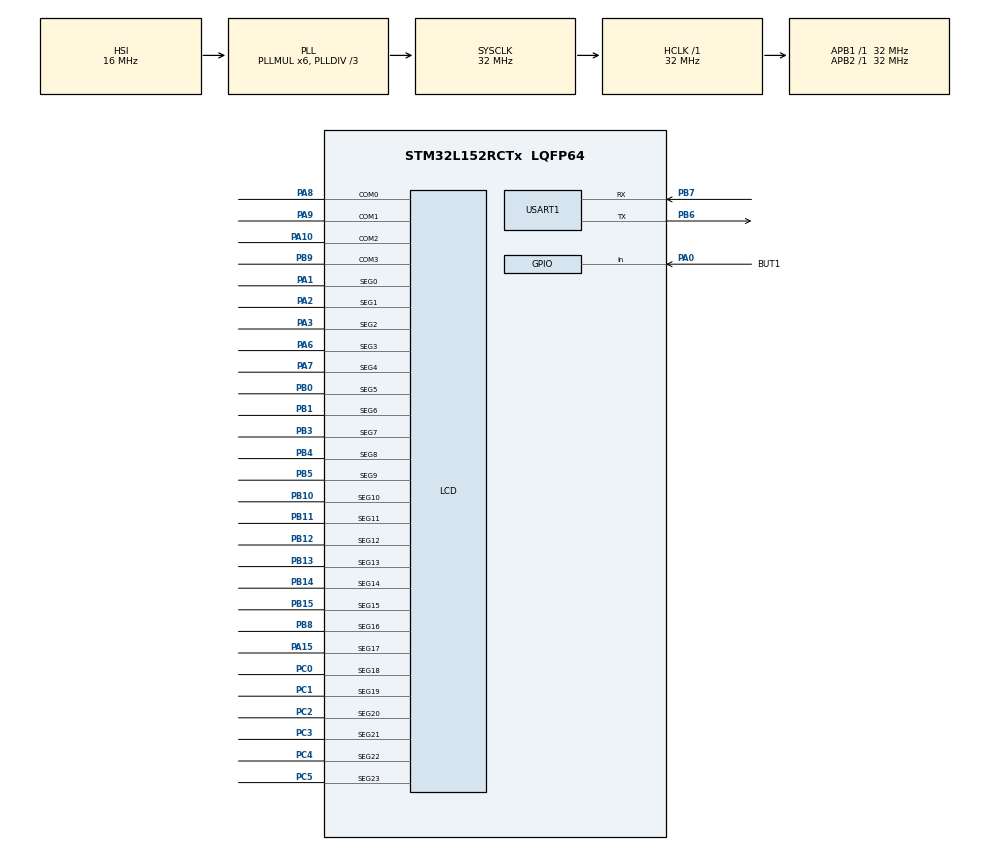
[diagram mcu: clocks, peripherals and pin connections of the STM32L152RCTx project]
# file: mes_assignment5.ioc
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LCD.Bias=LCD_BIAS_1_3
Mcu.Family=STM32L1
Mcu.Name=STM32L152RCTx
Mcu.Package=LQFP64
NVIC.PriorityGroup=NVIC_PRIORITYGROUP_0
NVIC.USART1_IRQn=true\:0\:0\:false\:false\:true\:true\:true\:true
PA0-WKUP1.GPIO_Label=BUT1
PA0-WKUP1.GPIO_PuPd=GPIO_PULLDOWN
PA0-WKUP1.Signal=GPIO_Input
PA1.Mode=SEG0
PA1.Signal=LCD_SEG0
PA10.Mode=1/4 Duty Cycle
PA10.Signal=LCD_COM2
PA15.Mode=SEG17
PA15.Signal=LCD_SEG17
PA2.Mode=SEG1
PA2.Signal=LCD_SEG1
PA3.Mode=SEG2
PA3.Signal=LCD_SEG2
PA6.Mode=SEG3
PA6.Signal=LCD_SEG3
PA7.Mode=SEG4
PA7.Signal=LCD_SEG4
PA8.Mode=1/4 Duty Cycle
PA8.Signal=LCD_COM0
PA9.Mode=1/4 Duty Cycle
PA9.Signal=LCD_COM1
PB0.Mode=SEG5
PB0.Signal=LCD_SEG5
PB1.Mode=SEG6
PB1.Signal=LCD_SEG6
PB10.Mode=SEG10
PB10.Signal=LCD_SEG10
PB11.Mode=SEG11
PB11.Signal=LCD_SEG11
PB12.Mode=SEG12
PB12.Signal=LCD_SEG12
PB13.Mode=SEG13
PB13.Signal=LCD_SEG13
PB14.Mode=SEG14
PB14.Signal=LCD_SEG14
PB15.Mode=SEG15
PB15.Signal=LCD_SEG15
PB3.Mode=SEG7
PB3.Signal=LCD_SEG7
PB4.Mode=SEG8
PB4.Signal=LCD_SEG8
PB5.Mode=SEG9
PB5.Signal=LCD_SEG9
PB6.Mode=Asynchronous
PB6.Signal=USART1_TX
PB7.Mode=Asynchronous
PB7.Signal=USART1_RX
PB8.Mode=SEG16
PB8.Signal=LCD_SEG16
PB9.Mode=1/4 Duty Cycle
PB9.Signal=LCD_COM3
PC0.Mode=SEG18
PC0.Signal=LCD_SEG18
PC1.Mode=SEG19
PC1.Signal=LCD_SEG19
PC2.Mode=SEG20
PC2.Signal=LCD_SEG20
PC3.Mode=SEG21
PC3.Signal=LCD_SEG21
PC4.Mode=SEG22
PC4.Signal=LCD_SEG22
PC5.Mode=SEG23
PC5.Signal=LCD_SEG23
ProjectManager.HeapSize=0x200
ProjectManager.StackSize=0x400
ProjectManager.TargetToolchain=STM32CubeIDE
RCC.48MHZClocksFreq_Value=48000000
RCC.AHBFreq_Value=32000000
RCC.APB1Freq_Value=32000000
RCC.APB1TimFreq_Value=32000000
RCC.APB2Freq_Value=32000000
RCC.APB2TimFreq_Value=32000000
RCC.HCLKFreq_Value=32000000
RCC.HSE_VALUE=8000000
RCC.HSI_VALUE=16000000
RCC.LSE_VALUE=32768
RCC.MSI_VALUE=2097000
RCC.PLLDIV=RCC_PLL_DIV3
RCC.PLLMUL=RCC_PLL_MUL6
RCC.RTCClockSelection=RCC_RTCCLKSOURCE_LSI
RCC.RTCClockSelectionVirtual=RCC_RTCCLKSOURCE_LSE
RCC.SYSCLKFreq_VALUE=32000000
RCC.SYSCLKSource=RCC_SYSCLKSOURCE_PLLCLK
RCC.USBOutput=48000000
RCC.VCOOutputFreq_Value=96000000
TIM5.Period=4294967295
TIM5.Prescaler=32000
USART1.VirtualMode=VM_ASYNC
VP_LCD_LCD_mux.Mode=Multiplex
VP_TIM5_VS_ClockSourceINT.Mode=Internal
board=STM32L152C-DISCO

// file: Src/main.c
/* USER CODE BEGIN Header */
/**
  ******************************************************************************
  * @file           : main.c
  * @brief          : Main program body
  ******************************************************************************
  * @attention
  *
  * Copyright (c) 2023 STMicroelectronics.
  * All rights reserved.
  *
  * This software is licensed under terms that can be found in the LICENSE file
  * in the root directory of this software component.
  * If no LICENSE file comes with this software, it is provided AS-IS.
  *
  ******************************************************************************
  */
/* USER CODE END Header */
#include "main.h"

/* USER CODE BEGIN Includes */
#include "stm32l152c_discovery_glass_lcd.h"
#include "console.h"
#include "applicationCommands.h"
/* USER CODE END Includes */

TIM_HandleTypeDef htim5;

UART_HandleTypeDef huart1;

void SystemClock_Config(void);
static void MX_GPIO_Init(void);
static void MX_USART1_UART_Init(void);
static void MX_TIM5_Init(void);

int main(void)
{

  /* MCU Configuration--------------------------------------------------------*/

  /* Reset of all peripherals, Initializes the Flash interface and the Systick. */
  HAL_Init();

  /* Configure the system clock */
  SystemClock_Config();

  /* Initialize all configured peripherals */
  MX_GPIO_Init();
  MX_USART1_UART_Init();
  MX_TIM5_Init();
  /* USER CODE BEGIN 2 */
  BSP_LCD_GLASS_Init();

  ConsoleInit();

  HAL_TIM_Base_Start_IT(&htim5);
  /* USER CODE END 2 */

  /* Infinite loop */
  while (1)
  {

    /* USER CODE BEGIN 3 */
    ConsoleProcess();
  }
  /* USER CODE END 3 */
}

void SystemClock_Config(void)
{
  RCC_OscInitTypeDef RCC_OscInitStruct = {0};
  RCC_ClkInitTypeDef RCC_ClkInitStruct = {0};
  RCC_PeriphCLKInitTypeDef PeriphClkInit = {0};

  /** Configure the main internal regulator output voltage
  */
  __HAL_PWR_VOLTAGESCALING_CONFIG(PWR_REGULATOR_VOLTAGE_SCALE1);

  /** Initializes the RCC Oscillators according to the specified parameters
  * in the RCC_OscInitTypeDef structure.
  */
  RCC_OscInitStruct.OscillatorType = RCC_OSCILLATORTYPE_HSI|RCC_OSCILLATORTYPE_LSI;
  RCC_OscInitStruct.HSIState = RCC_HSI_ON;
  RCC_OscInitStruct.HSICalibrationValue = RCC_HSICALIBRATION_DEFAULT;
  RCC_OscInitStruct.LSIState = RCC_LSI_ON;
  RCC_OscInitStruct.PLL.PLLState = RCC_PLL_ON;
  RCC_OscInitStruct.PLL.PLLSource = RCC_PLLSOURCE_HSI;
  RCC_OscInitStruct.PLL.PLLMUL = RCC_PLL_MUL6;
  RCC_OscInitStruct.PLL.PLLDIV = RCC_PLL_DIV3;
  if (HAL_RCC_OscConfig(&RCC_OscInitStruct) != HAL_OK)
  {
    Error_Handler();
  }

  /** Initializes the CPU, AHB and APB buses clocks
  */
  RCC_ClkInitStruct.ClockType = RCC_CLOCKTYPE_HCLK|RCC_CLOCKTYPE_SYSCLK
                              |RCC_CLOCKTYPE_PCLK1|RCC_CLOCKTYPE_PCLK2;
  RCC_ClkInitStruct.SYSCLKSource = RCC_SYSCLKSOURCE_PLLCLK;
  RCC_ClkInitStruct.AHBCLKDivider = RCC_SYSCLK_DIV1;
  RCC_ClkInitStruct.APB1CLKDivider = RCC_HCLK_DIV1;
  RCC_ClkInitStruct.APB2CLKDivider = RCC_HCLK_DIV1;

  if (HAL_RCC_ClockConfig(&RCC_ClkInitStruct, FLASH_LATENCY_1) != HAL_OK)
  {
    Error_Handler();
  }
  PeriphClkInit.PeriphClockSelection = RCC_PERIPHCLK_RTC|RCC_PERIPHCLK_LCD;
  PeriphClkInit.RTCClockSelection = RCC_RTCCLKSOURCE_LSI;
  PeriphClkInit.LCDClockSelection = RCC_RTCCLKSOURCE_LSI;

  if (HAL_RCCEx_PeriphCLKConfig(&PeriphClkInit) != HAL_OK)
  {
    Error_Handler();
  }
}

static void MX_TIM5_Init(void)
{

  TIM_ClockConfigTypeDef sClockSourceConfig = {0};
  TIM_MasterConfigTypeDef sMasterConfig = {0};

  htim5.Instance = TIM5;
  htim5.Init.Prescaler = 32000;
  htim5.Init.CounterMode = TIM_COUNTERMODE_UP;
  htim5.Init.Period = 4294967295;
  htim5.Init.ClockDivision = TIM_CLOCKDIVISION_DIV1;
  htim5.Init.AutoReloadPreload = TIM_AUTORELOAD_PRELOAD_DISABLE;
  if (HAL_TIM_Base_Init(&htim5) != HAL_OK)
  {
    Error_Handler();
  }
  sClockSourceConfig.ClockSource = TIM_CLOCKSOURCE_INTERNAL;
  if (HAL_TIM_ConfigClockSource(&htim5, &sClockSourceConfig) != HAL_OK)
  {
    Error_Handler();
  }
  sMasterConfig.MasterOutputTrigger = TIM_TRGO_RESET;
  sMasterConfig.MasterSlaveMode = TIM_MASTERSLAVEMODE_DISABLE;
  if (HAL_TIMEx_MasterConfigSynchronization(&htim5, &sMasterConfig) != HAL_OK)
  {
    Error_Handler();
  }

}

static void MX_USART1_UART_Init(void)
{

  huart1.Instance = USART1;
  huart1.Init.BaudRate = 115200;
  huart1.Init.WordLength = UART_WORDLENGTH_8B;
  huart1.Init.StopBits = UART_STOPBITS_1;
  huart1.Init.Parity = UART_PARITY_NONE;
  huart1.Init.Mode = UART_MODE_TX_RX;
  huart1.Init.HwFlowCtl = UART_HWCONTROL_NONE;
  huart1.Init.OverSampling = UART_OVERSAMPLING_16;
  if (HAL_UART_Init(&huart1) != HAL_OK)
  {
    Error_Handler();
  }

}

static void MX_GPIO_Init(void)
{
  GPIO_InitTypeDef GPIO_InitStruct = {0};

  /* GPIO Ports Clock Enable */
  __HAL_RCC_GPIOC_CLK_ENABLE();
  __HAL_RCC_GPIOA_CLK_ENABLE();
  __HAL_RCC_GPIOB_CLK_ENABLE();

  /*Configure GPIO pin : BUT1_Pin */
  GPIO_InitStruct.Pin = BUT1_Pin;
  GPIO_InitStruct.Mode = GPIO_MODE_INPUT;
  GPIO_InitStruct.Pull = GPIO_PULLDOWN;
  HAL_GPIO_Init(BUT1_GPIO_Port, &GPIO_InitStruct);

}

void Error_Handler(void)
{
  __disable_irq();
  while (1)
  {
  }
}
